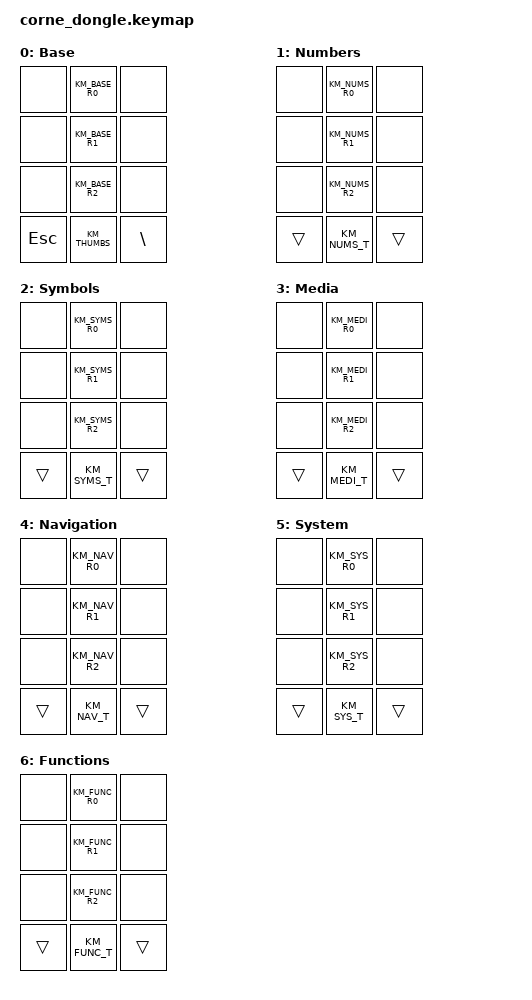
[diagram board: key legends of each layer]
/*
 * Copyright (c) 2024 The ZMK Contributors
 * SPDX-License-Identifier: MIT
 */

#include <behaviors.dtsi>
#include <dt-bindings/zmk/keys.h>
#include <dt-bindings/zmk/bt.h>
#include <dt-bindings/zmk/outputs.h>
#include <dt-bindings/zmk/rgb.h>
#include <dt-bindings/zmk/ext_power.h>
#include <dt-bindings/zmk/reset.h>
#include "../../../behaviors/character_map.dtsi"
#include "../../../behaviors/homerow_mods.dtsi"
#include "../../../behaviors/keymap_layers.h"

&soft_off   { hold-time-ms = <5000>; };
&lt         { tapping-term-ms = <200>; quick_tap_ms = <200>; };

/ {
    KM_COND_LAYERS

    keymap {
        compatible = "zmk,keymap";

        // Corne has outer &none columns (rows 0-2) and Totem outer key positions
        // in the thumb row: RC(3,1)=ESC and RC(3,10)=BSLH from the dongle transform.
        // Layout per layer: [outer]  KM_*_R0  [outer]   (12 bindings × 3 rows)
        //                   [ESC]  KM_*_T  [BSLH]      (8 bindings thumb row)

        base_layer {
            display-name = "Base";
            bindings = <
                &none  KM_BASE_R0  &none
                &none  KM_BASE_R1  &none
                &none  KM_BASE_R2  &none
                &kp ESC  KM_THUMBS  &kp BSLH
            >;
            // Left slot: arrows (CW = right, CCW = left) — for future builds.
            // Right slot (mounted): PgUp (CW) / PgDn (CCW).
            sensor-bindings = <&inc_dec_kp RIGHT LEFT &inc_dec_kp PG_UP PG_DN>;
        };

        numbers_layer {
            display-name = "Numbers";
            bindings = <
                &none  KM_NUMS_R0  &none
                &none  KM_NUMS_R1  &none
                &none  KM_NUMS_R2  &none
                &trans  KM_NUMS_T  &trans
            >;
            // Right encoder only (left slot cleared).
            sensor-bindings = <&sensor_none 0 0 &inc_dec_kp LC(LEFT) LC(RIGHT)>;
        };

        symbols_layer {
            display-name = "Symbols";
            bindings = <
                &none  KM_SYMS_R0  &none
                &none  KM_SYMS_R1  &none
                &none  KM_SYMS_R2  &none
                &trans  KM_SYMS_T  &trans
            >;
            // Left encoder only (right slot cleared).
            sensor-bindings = <&inc_dec_kp C_BRI_DN C_BRI_UP &sensor_none 0 0>;
        };

        media_layer {
            display-name = "Media";
            bindings = <
                &none  KM_MEDI_R0  &none
                &none  KM_MEDI_R1  &none
                &none  KM_MEDI_R2  &none
                &trans  KM_MEDI_T  &trans
            >;
            sensor-bindings = <&sensor_none 0 0 &inc_dec_kp C_PREV C_NEXT>;
        };

        nav_layer {
            display-name = "Navigation";
            bindings = <
                &none  KM_NAV_R0  &none
                &none  KM_NAV_R1  &none
                &none  KM_NAV_R2  &none
                &trans  KM_NAV_T  &trans
            >;
            sensor-bindings = <&sensor_none 0 0 &inc_dec_kp LEFT RIGHT>;
        };

        system_layer {
            display-name = "System";
            bindings = <
                &none  KM_SYS_R0  &none
                &none  KM_SYS_R1  &none
                &none  KM_SYS_R2  &none
                &trans  KM_SYS_T  &trans
            >;
            // Left encoder only (right slot cleared).
            sensor-bindings = <&inc_dec_kp C_VOL_DN C_VOL_UP &sensor_none 0 0>;
        };

        functions_layer {
            display-name = "Functions";
            bindings = <
                &none  KM_FUNC_R0  &none
                &none  KM_FUNC_R1  &none
                &none  KM_FUNC_R2  &none
                &trans  KM_FUNC_T  &trans
            >;
            sensor-bindings = <&inc_dec_kp C_VOL_DN C_VOL_UP &sensor_none 0 0>;
        };
    };
};
